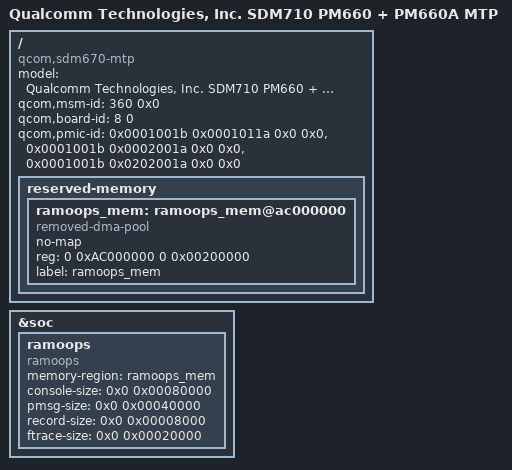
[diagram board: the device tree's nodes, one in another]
/* Copyright (c) 2018, The Linux Foundation. All rights reserved.
 *
 * This program is free software; you can redistribute it and/or modify
 * it under the terms of the GNU General Public License version 2 and
 * only version 2 as published by the Free Software Foundation.
 *
 * This program is distributed in the hope that it will be useful,
 * but WITHOUT ANY WARRANTY; without even the implied warranty of
 * MERCHANTABILITY or FITNESS FOR A PARTICULAR PURPOSE.  See the
 * GNU General Public License for more details.
 */

/dts-v1/;
/plugin/;

#define CONFIG_VENDOR_SMARTISAN

#include <dt-bindings/clock/qcom,gcc-sdm845.h>
#include <dt-bindings/clock/qcom,camcc-sdm845.h>
#include <dt-bindings/clock/qcom,dispcc-sdm845.h>
#include <dt-bindings/clock/qcom,rpmh.h>
#include <dt-bindings/interrupt-controller/arm-gic.h>

#include "sdm670-mtp.dtsi"
#include "pm660a.dtsi"
//#include "sdm670-audio-overlay.dtsi"
#include "ocean-audio-overlay.dtsi"
#include "ocean-charger.dtsi"
#include "ocean-haptics-overlay.dtsi"

/ {
	model = "Qualcomm Technologies, Inc. SDM710 PM660 + PM660A MTP";
	compatible = "qcom,sdm670-mtp", "qcom,sdm670", "qcom,mtp";
	qcom,msm-id = <360 0x0>;
	qcom,board-id = <8 0>;
	qcom,pmic-id = <0x0001001b 0x0001011a 0x0 0x0>,
		       <0x0001001b 0x0002001a 0x0 0x0>,
		       <0x0001001b 0x0202001a 0x0 0x0>;
};

/ {
	reserved-memory {
		ramoops_mem: ramoops_mem@ac000000 {
			compatible = "removed-dma-pool";
			no-map;
			reg = <0 0xAC000000 0 0x00200000>;
			label = "ramoops_mem";
		};
	};
};

&soc {
	ramoops {
		compatible = "ramoops";
		status = "ok";
		memory-region = <&ramoops_mem>;

		console-size = <0x0 0x00080000>;
		pmsg-size    = <0x0 0x00040000>;
		record-size  = <0x0 0x00008000>;
		ftrace-size  = <0x0 0x00020000>;
	};
};
